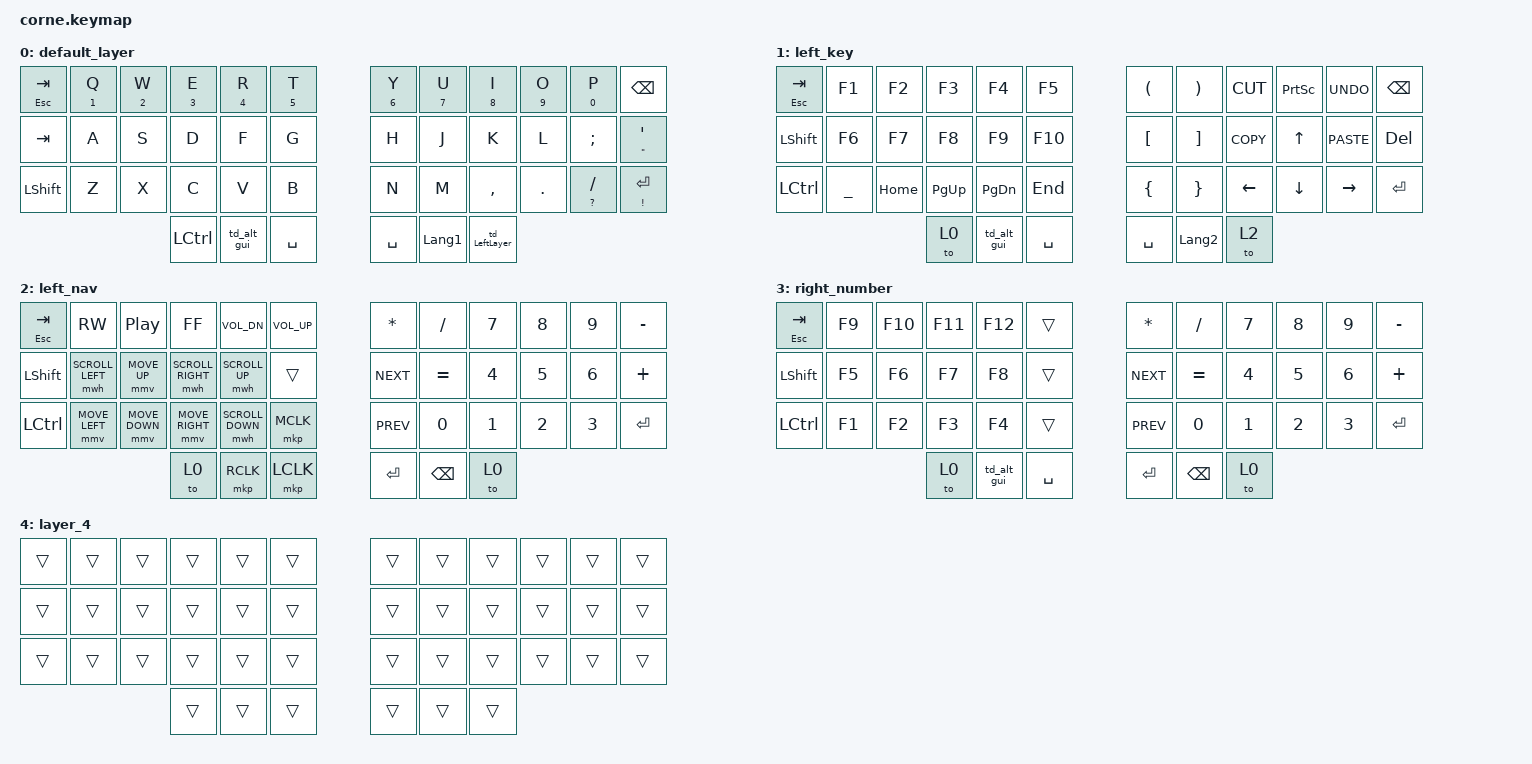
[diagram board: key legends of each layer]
#include <dt-bindings/zmk/mouse.h>
#include <behaviors.dtsi>
#include <dt-bindings/zmk/bt.h>
#include <dt-bindings/zmk/keys.h>

#define default_layer 0
#define left_key   1
#define left_nav   2
#define right_number   3
#define U_MOUSE_MOVE_MAX 1000                     /* <--- New max speed setting (default: 600) */

#undef MOVE_UP
#undef MOVE_DOWN
#undef MOVE_LEFT
#undef MOVE_RIGHT

#define MOVE_UP MOVE_VERT(-U_MOUSE_MOVE_MAX)
#define MOVE_DOWN MOVE_VERT(U_MOUSE_MOVE_MAX)
#define MOVE_LEFT MOVE_HOR(-U_MOUSE_MOVE_MAX)
#define MOVE_RIGHT MOVE_HOR(U_MOUSE_MOVE_MAX)

&mmv {
    time-to-max-speed-ms = <500>;             /* <--- How long time until max speed is reached (default: 500) */
};

#define U_MOUSE_SCROLL_MAX 20                    /* <--- New max speed setting (default: 10) */

#undef SCROLL_UP
#undef SCROLL_DOWN
#undef SCROLL_LEFT
#undef SCROLL_RIGHT

#define SCROLL_UP SCROLL_VERT(U_MOUSE_SCROLL_MAX)
#define SCROLL_DOWN SCROLL_VERT(-U_MOUSE_SCROLL_MAX)
#define SCROLL_LEFT SCROLL_HOR(-U_MOUSE_SCROLL_MAX)
#define SCROLL_RIGHT SCROLL_HOR(U_MOUSE_SCROLL_MAX)

&mwh {
    time-to-max-speed-ms = <0>;                 /* <--- How long time until max speed is reached */
};

&mt { tapping-term-ms = <500>; };

/ {
    behaviors {
        td_alt_gui: td_alt_gui {
            compatible = "zmk,behavior-tap-dance";
            label = "TD_ALT_GUI";
            #binding-cells = <0>;
            bindings = <&kp LEFT_ALT>, <&kp LGUI>;
        };

        td_LeftLayer: td_LeftLayer {
            compatible = "zmk,behavior-tap-dance";
            label = "TD_LEFTLAYER";
            #binding-cells = <0>;
            bindings = <&to 1>, <&to 2>;
        };

        ht: ht {
            compatible = "zmk,behavior-hold-tap";
            label = "HT";
            bindings = <&kp>, <&kp>;

            #binding-cells = <2>;
            tapping-term-ms = <500>;
            flavor = "tap-preferred";
        };
    };

    combos {
        compatible = "zmk,combos";

        reset {
            bindings = <&bt BT_CLR>;
            key-positions = <29 17 5>;
            layers = <3>;
        };
    };

    keymap {
        compatible = "zmk,keymap";

        default_layer {
            // -----------------------------------------------------------------------------------------
            // | TAB/ESC |  Q  |  W  |  E     |     R    |  T  |   |  Y  |  U   |  I  |  O  |  P  | ESC |
            // | SHIFT   |  A  |  S  |  D     |     F    |  G  |   |  H  |  J   |  K  |  L  |  ;  |  '  |
            // | CTRL    |  Z  |  X  |  C     |     V    |  B  |   |  B  |  N   |  M  |  ,  |  .  |  /  |
            //                       | td1,2 |     LALT | SPC |   | ENT | BKSP | RSE |

            bindings = <
&ht ESC TAB  &ht N1 Q  &ht N2 W  &ht N3 E   &ht N4 R     &ht N5 T     &ht N6 Y   &ht N7 U        &ht N8 I       &ht N9 O    &ht N0 P            &kp BSPC
&kp TAB      &kp A     &kp S     &kp D      &kp F        &kp G        &kp H      &kp J           &kp K          &kp L       &kp SEMI            &ht DOUBLE_QUOTES SINGLE_QUOTE
&kp LSHFT    &kp Z     &kp X     &kp C      &kp V        &kp B        &kp N      &kp M           &kp COMMA      &kp PERIOD  &ht QUESTION SLASH  &ht EXCLAMATION RET
                                 &kp LCTRL  &td_alt_gui  &kp SPACE    &kp SPACE  &kp LANGUAGE_1  &td_LeftLayer
            >;
        };

        left_key {
            // -----------------------------------------------------------------------------------------
            // | TAB/ESC |  Q  |  W  |  E  |  R   |  T  |   | C_FF     | C_RW     | PSCRN |  Play/Pause   | PAGE_UP    | ESC    |
            // | SHIFT   |  A  |  S  |  D  |  F   |  G  |   | C_BRI_UP | C_VOL_UP |  DEL  |      UP       | PAGE_DOUWN | trans |
            // | CTRL    |  Z  |  X  |  C  |  V   |  B  |   | C_BRI_DN | C_VOL_DN |  LFT  |     DWN       |    RGT     | RALT   |
            //                       | def | LALT | SPC |   | ENT      |   BKSP   |  GUI  |

            bindings = <
&mt ESC TAB  &kp F1          &kp F2    &kp F3       &kp F4         &kp F5       &kp LPAR   &kp RPAR        &kp K_CUT   &kp PRINTSCREEN  &kp K_UNDO   &kp BSPC
&kp LSHFT    &kp F6          &kp F7    &kp F8       &kp F9         &kp F10      &kp LBKT   &kp RBKT        &kp K_COPY  &kp UP           &kp K_PASTE  &kp DEL
&kp LCTRL    &kp UNDERSCORE  &kp HOME  &kp PAGE_UP  &kp PAGE_DOWN  &kp END      &kp LBRC   &kp RBRC        &kp LEFT    &kp DOWN         &kp RIGHT    &kp RET
                                       &to 0        &td_alt_gui    &kp SPACE    &kp SPACE  &kp LANGUAGE_2  &to 2
            >;
        };

        left_nav {
            // -----------------------------------------------------------------------------------------
            // | TAB/ESC |  C_RW    |  Pause/Play  |  C_FF    | VOP_DN   |  VOL_UP |   |  Y  |  U   |  I  |  O  |  P  | ESC |
            // | SHIFT   |  Prev    |  M_Up        |  Next    | PG_UP    |  HOME   |   |  H  |  J   | DEL |  UP |  ;  |  '  |
            // | CTRL    |  M_Left  |  M_Down      |  M_Right | PG_DOWN  |  END    |   |  B  |  N   | LFT | DWN | RGT |  /  |
            //                                     | to0      | Menu     |  LCLK   |   | ENT | BKSP | to0 |

            bindings = <
&mt ESC TAB  &kp C_RW          &kp C_PP        &kp C_FF           &kp C_VOL_DN      &kp C_VOL_UP    &kp ASTERISK  &kp SLASH  &kp N7  &kp N8  &kp N9  &kp MINUS
&kp LSHFT    &mwh SCROLL_LEFT  &mmv MOVE_UP    &mwh SCROLL_RIGHT  &mwh SCROLL_UP    &trans          &kp K_NEXT    &kp EQUAL  &kp N4  &kp N5  &kp N6  &kp PLUS
&kp LCTRL    &mmv MOVE_LEFT    &mmv MOVE_DOWN  &mmv MOVE_RIGHT    &mwh SCROLL_DOWN  &mkp MCLK       &kp K_PREV    &kp N0     &kp N1  &kp N2  &kp N3  &kp RET
                                               &to 0              &mkp RCLK         &mkp LCLK       &kp RET       &kp BSPC   &to 0
            >;
        };

        right_number {
            // -----------------------------------------------------------------------------------------
            // | TAB/ESC |  1  |  2  |  3  |  4   |  5  |   |  6  |  7   |  8  |  9  |  0  | ESC  |
            // | SHIFT   | F1  | F2  | F3  | F4   | F5  |   |  -  |  =   |  \  |  UP |  /  |  *   |
            // | CTRL    | F6  | F7  | F8  | F9   | F10 |   |  [  |  ]   | LFT | DWN | RGT |  `   |
            //                       | GUI | LALT | SPC |   | ENT | BKSP | def |

            bindings = <
&mt ESC TAB  &kp F9  &kp F10  &kp F11  &kp F12      &trans       &kp ASTERISK  &kp SLASH  &kp N7  &kp N8  &kp N9  &kp MINUS
&kp LSHFT    &kp F5  &kp F6   &kp F7   &kp F8       &trans       &kp K_NEXT    &kp EQUAL  &kp N4  &kp N5  &kp N6  &kp PLUS
&kp LCTRL    &kp F1  &kp F2   &kp F3   &kp F4       &trans       &kp K_PREV    &kp N0     &kp N1  &kp N2  &kp N3  &kp RET
                              &to 0    &td_alt_gui  &kp SPACE    &kp RET       &kp BSPC   &to 0
            >;
        };

        layer_4 {
            bindings = <
&trans  &trans  &trans  &trans  &trans  &trans    &trans  &trans  &trans  &trans  &trans  &trans
&trans  &trans  &trans  &trans  &trans  &trans    &trans  &trans  &trans  &trans  &trans  &trans
&trans  &trans  &trans  &trans  &trans  &trans    &trans  &trans  &trans  &trans  &trans  &trans
                        &trans  &trans  &trans    &trans  &trans  &trans
            >;
        };
    };
};
